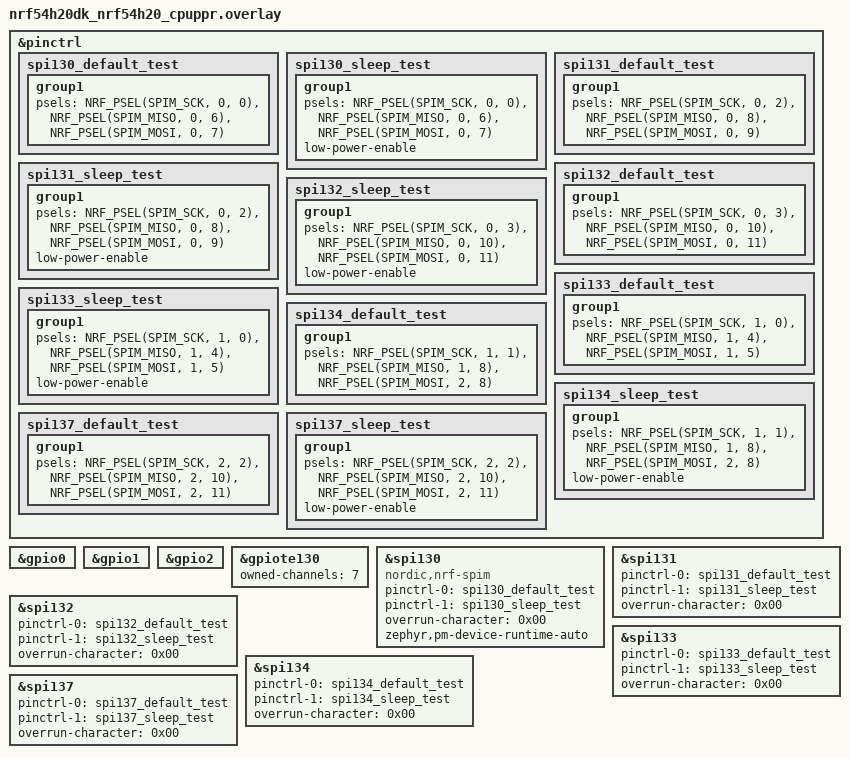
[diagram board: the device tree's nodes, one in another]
/*
 * Copyright (c) 2025 Nordic Semiconductor ASA
 *
 * SPDX-License-Identifier: LicenseRef-Nordic-5-Clause
 */

&pinctrl {
	spi130_default_test: spi130_default_test {
		group1 {
			psels = <NRF_PSEL(SPIM_SCK, 0, 0)>,
				<NRF_PSEL(SPIM_MISO, 0, 6)>,
				<NRF_PSEL(SPIM_MOSI, 0, 7)>;
		};
	};

	spi130_sleep_test: spi130_sleep_test {
		group1 {
			psels = <NRF_PSEL(SPIM_SCK, 0, 0)>,
				<NRF_PSEL(SPIM_MISO, 0, 6)>,
				<NRF_PSEL(SPIM_MOSI, 0, 7)>;
			low-power-enable;
		};
	};

	spi131_default_test: spi131_default_test {
		group1 {
			psels = <NRF_PSEL(SPIM_SCK, 0, 2)>,
				<NRF_PSEL(SPIM_MISO, 0, 8)>,
				<NRF_PSEL(SPIM_MOSI, 0, 9)>;
		};
	};

	spi131_sleep_test: spi131_sleep_test {
		group1 {
			psels = <NRF_PSEL(SPIM_SCK, 0, 2)>,
				<NRF_PSEL(SPIM_MISO, 0, 8)>,
				<NRF_PSEL(SPIM_MOSI, 0, 9)>;
			low-power-enable;
		};
	};

	spi132_default_test: spi132_default_test {
		group1 {
			psels = <NRF_PSEL(SPIM_SCK, 0, 3)>,
				<NRF_PSEL(SPIM_MISO, 0, 10)>,
				<NRF_PSEL(SPIM_MOSI, 0, 11)>;
		};
	};

	spi132_sleep_test: spi132_sleep_test {
		group1 {
			psels = <NRF_PSEL(SPIM_SCK, 0, 3)>,
				<NRF_PSEL(SPIM_MISO, 0, 10)>,
				<NRF_PSEL(SPIM_MOSI, 0, 11)>;
			low-power-enable;
		};
	};

	spi133_default_test: spi133_default_test {
		group1 {
			psels = <NRF_PSEL(SPIM_SCK, 1, 0)>,
				<NRF_PSEL(SPIM_MISO, 1, 4)>,
				<NRF_PSEL(SPIM_MOSI, 1, 5)>;
		};
	};

	spi133_sleep_test: spi133_sleep_test {
		group1 {
			psels = <NRF_PSEL(SPIM_SCK, 1, 0)>,
				<NRF_PSEL(SPIM_MISO, 1, 4)>,
				<NRF_PSEL(SPIM_MOSI, 1, 5)>;
			low-power-enable;
		};
	};

	spi134_default_test: spi134_default_test {
		group1 {
			psels = <NRF_PSEL(SPIM_SCK, 1, 1)>,
				<NRF_PSEL(SPIM_MISO, 1, 8)>,
				<NRF_PSEL(SPIM_MOSI, 2, 8)>;
		};
	};

	spi134_sleep_test: spi134_sleep_test {
		group1 {
			psels = <NRF_PSEL(SPIM_SCK, 1, 1)>,
				<NRF_PSEL(SPIM_MISO, 1, 8)>,
				<NRF_PSEL(SPIM_MOSI, 2, 8)>;
			low-power-enable;
		};
	};

	spi137_default_test: spi137_default_test {
		group1 {
			psels = <NRF_PSEL(SPIM_SCK, 2, 2)>,
				<NRF_PSEL(SPIM_MISO, 2, 10)>,
				<NRF_PSEL(SPIM_MOSI, 2, 11)>;
		};
	};

	spi137_sleep_test: spi137_sleep_test {
		group1 {
			psels = <NRF_PSEL(SPIM_SCK, 2, 2)>,
				<NRF_PSEL(SPIM_MISO, 2, 10)>,
				<NRF_PSEL(SPIM_MOSI, 2, 11)>;
			low-power-enable;
		};
	};
};

&gpio0 {
	status = "okay";
};

&gpio1 {
	status = "okay";
};

&gpio2 {
	status = "okay";
};

&gpiote130 {
	status = "okay";
	owned-channels = <7>;
};

/* PPR does not have interrupts for fast peripherals spi120 and spi121. */

&spi130 {
	compatible = "nordic,nrf-spim";
	status = "okay";
	pinctrl-0 = <&spi130_default_test>;
	pinctrl-1 = <&spi130_sleep_test>;
	pinctrl-names = "default", "sleep";
	overrun-character = <0x00>;
	zephyr,pm-device-runtime-auto;
};

&spi131 {
	status = "okay";
	pinctrl-0 = <&spi131_default_test>;
	pinctrl-1 = <&spi131_sleep_test>;
	pinctrl-names = "default", "sleep";
	overrun-character = <0x00>;
};

&spi132 {
	status = "okay";
	pinctrl-0 = <&spi132_default_test>;
	pinctrl-1 = <&spi132_sleep_test>;
	pinctrl-names = "default", "sleep";
	overrun-character = <0x00>;
};

&spi133 {
	status = "okay";
	pinctrl-0 = <&spi133_default_test>;
	pinctrl-1 = <&spi133_sleep_test>;
	pinctrl-names = "default", "sleep";
	overrun-character = <0x00>;
};

&spi134 {
	status = "okay";
	pinctrl-0 = <&spi134_default_test>;
	pinctrl-1 = <&spi134_sleep_test>;
	pinctrl-names = "default", "sleep";
	overrun-character = <0x00>;
};

/* spi135 inaccessible due to cpuppr console on uart135 */

/* spi136 inaccessible due to cpuapp console on uart136 */

&spi137 {
	status = "okay";
	pinctrl-0 = <&spi137_default_test>;
	pinctrl-1 = <&spi137_sleep_test>;
	pinctrl-names = "default", "sleep";
	overrun-character = <0x00>;
};
